# MB9BF51xR register map
File version: 1.7
Registers are 8-bit, read-write, reset 0x0 unless marked. A register's access mark holds for its fields unless they carry their own. Offsets are from the block's base; lines under a group give offsets from that group; [hi:lo] are bit positions; {n}, {i} and the like mark numbered series; 'fields as' and 'values as' point back to an identical list; <NAME> marks a mode.

## Memory map
0x200E0000 WORKFLASH_IF size 0xC — WorkFlash Memory
0x40000000 FLASH_IF blocks up to offset 0x104 — Flash Memory
0x40010000 CRG blocks up to offset 0x69 — Clock Unit Registers
0x40011000 HWWDT blocks up to offset 0xC04 — Hardware Watchdog Timer
0x40012000 SWWDT blocks up to offset 0xC04 — Software Watchdog Timer
0x40015000 DTIM blocks up to offset 0x3C — Dual Timer
0x40020000 MFT0 blocks up to offset 0xC2 — Multifunction Timer 0
0x40021000 MFT1 blocks up to offset 0xC2
0x40022000 MFT2 blocks up to offset 0xC2
0x40024000 MFT_PPG blocks up to offset 0x359 — PPG Configuration
0x40025000 BT0 blocks up to offset 0x12 — Base Timer 0
0x40025040 BT1 blocks up to offset 0x12
0x40025080 BT2 blocks up to offset 0x12
0x400250C0 BT3 blocks up to offset 0x12
0x40025100 BTIOSEL03 size 0x2 — Base Timer I/O Select
0x40025200 BT4 blocks up to offset 0x12
0x40025240 BT5 blocks up to offset 0x12
0x40025280 BT6 blocks up to offset 0x12
0x400252C0 BT7 blocks up to offset 0x12
0x40025300 BTIOSEL47 blocks up to offset 0x2 — Base Timer I/O Select
0x40025F00 SBSSR blocks up to offset 0xFE — Software-based Simultaneous Startup Register
0x40026000 QPRC0 blocks up to offset 0x40 — Quadrature Position/Revolution Counter 0
0x40026040 QPRC1 blocks up to offset 0x40
0x40026080 QPRC2 blocks up to offset 0x40
0x40027000 ADC0 blocks up to offset 0x3D — ADC0 Registers
0x40027100 ADC1 blocks up to offset 0x3D
0x40027200 ADC2 blocks up to offset 0x3D
0x4002E000 CRTRIM blocks up to offset 0x10 — CR Trimming Registers
0x40030000 EXTI blocks up to offset 0x19 — External Interrupt and NMI Control
0x40031000 INTREQ blocks up to offset 0x218 — Interrupts
0x40033000 GPIO size 0x740 — General-purpose I/O ports
0x40035000 LVD blocks up to offset 0x11 — Low-voltage Detection
0x40036000 USBCLK blocks up to offset 0x31 — USB Clock
0x40037000 CANPRES size 0x1 — CAN Prescaler Register
0x40038000 MFS0 blocks up to offset 0x12 — Multi-function Serial Interface 0
0x40038100 MFS1 blocks up to offset 0x12
0x40038200 MFS2 blocks up to offset 0x12
0x40038300 MFS3 blocks up to offset 0x12
0x40038400 MFS4 blocks up to offset 0x1A — Multi-function Serial Interface 4
0x40038500 MFS5 blocks up to offset 0x1A
0x40038600 MFS6 blocks up to offset 0x1A
0x40038700 MFS7 blocks up to offset 0x1A
0x40038800 MFS_NFC size 0x2 — I2C Auxiliary Noise Filter Setting Register
0x40039000 CRC blocks up to offset 0x10 — CRC Registers
0x4003A000 WC blocks up to offset 0x15 — Watch Counter
0x4003B000 RTC blocks up to offset 0x2A — REAL-TIME CLOCK
0x4003F000 EXBUS blocks up to offset 0x304 — External Bus Interface
0x40040000 USB0 blocks up to offset 0x2176 — USB0 Function
0x40060000 DMAC blocks up to offset 0x90 — DMAC Registers
0x40062000 CAN0 blocks up to offset 0xB4 — CAN0 Registers
0x40063000 CAN1 blocks up to offset 0xB4

## Interrupts
0 CSV (CRG)
1 SWDT (SWWDT)
2 LVD
3 WFG (MFT0)
4 EXTINT0_7 (EXTI)
5 EXTINT8_15 (EXTI)
6 DTIM_QDU (DTIM)
{2n+7} MFS{n}RX (MFS{n}) (n=0..7)
{2n+8} MFS{n}TX (MFS{n}) (n=0..7)
23 PPG (MFT_PPG)
24 OSC_PLL_WC (CRG)
25 ADC0
26 ADC1
27 ADC2
28 FRTIM (MFT0)
29 INCAP (MFT0)
30 OUTCOMP (MFT0)
31 BTIM0_7 (BT0)
32 CAN0
33 CAN1
34 USB0F (USB0)
35 USB0F_USB0H (USB0)
{n+38} DMAC{n} (DMAC) (n=0..7)

## WORKFLASH_IF — WorkFlash Memory
Base 0x200E0000
0x00 WFASZR 32-bit reset 0x1 — WorkFlash Access Size Register
  [0] ASZ — WorkFlash Access Size
0x04 WFRWTR 32-bit reset 0x2 — WorkFlash Read Wait Register
  [2:0] RWT — Read Wait Cycle
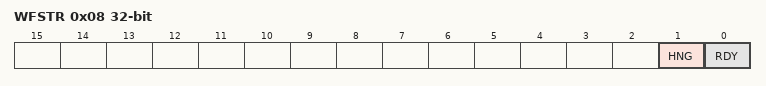
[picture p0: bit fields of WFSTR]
0x08 WFSTR 32-bit ro — WorkFlash Status Register
  [1] HNG — WorkFlash Hang
  [0] RDY — WorkFlash Rdy

## FLASH_IF — Flash Memory
Base 0x40000000
0x00 FASZR 32-bit reset 0x2 — Flash Access Size Register
  [1:0] ASZ — Flash Access Size
0x04 FRWTR 32-bit reset 0x2 — Flash Read Wait Register
  [1:0] RWT — Read Wait Cycle
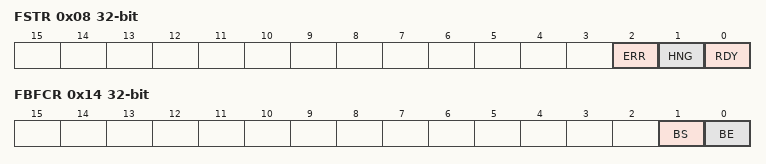
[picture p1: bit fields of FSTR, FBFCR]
0x08 FSTR 32-bit ro — Flash Status Register
  [2] ERR rw — Flash ECC Error
  [1] HNG — Flash Hang flag
  [0] RDY — Flash Rdy
0x10 FSYNDN 32-bit — Flash Sync Down Register
  [2:0] SD — Flash Sync
0x14 FBFCR 32-bit — Flash Buffer Control Register
  [1] BS ro — Buffer Status
  [0] BE — Buffer Enable
0x100 CRTRMM 32-bit ro reset not defined — CR Trimming Data Mirror Register
  [9:0] TRMM — CR Trimming Data Mirror

## Notices in the file
Licence Terms
FUJITSU SEMICONDUCTOR LIMITED (gLICENSORh) hereby grants and
you (gLICENSEEh) hereby accept a non transferable, non-exclusive
licence to use and copy the deliverables (gDeliverablesh) solely for
the purpose of; (i) developing LICENSEEfs development tools and
distributing such development tools to third parties; (ii) generating
derivative representations of the Deliverables to develop and debug
software for LICENSORfs targeted devices or device series identified
within the Deliverables, (together the gPurposeh) under the following
terms and conditions:
1. Ownership.
The Deliverables are the property of LICENSOR. LICENSEE acquires no
right, title or interest in the Deliverables other than the licence
rights granted herein.
2. Use.
LICENSEE shall only be permitted to use the Deliverables for the
Purpose. LICENSEE shall not reverse engineer, decompile or
disassemble the Deliverables, in whole or in part.
3. Copies.
All copies of the Deliverables must bear the same notice(s) contained
on the original copies of the Deliverables.
4. No Warranty.
THE DELIVERABLES ARE PROVIDED gAS ISh AND ANY EXPRESS, IMPLIED OR
STATUTORY WARRANTIES, INCLUDING, BUT NOT LIMITED TO, THE IMPLIED
WARRANTIES OF MERCHANTABILITY, SATISFACTORY QUALITY AND FITNESS FOR
A PARTICULAR PURPOSE ARE DISCLAIMED.
IN NO EVENT SHALL LICENSOR BE LIABLE FOR ANY DIRECT, INDIRECT,
INCIDENTAL, SPECIAL, EXEMPLARY, OR CONSEQUENTIAL DAMAGES HOWEVER CAUSED
AND ON ANY THEORY OF LIABILITY, WHETHER IN CONTRACT, STRICT LIABILITY,
OR TORT (INCLUDING NEGLIGENCE OR OTHERWISE) ARISING IN ANY WAY OUT OF
THE USE OF THE DELIVERABLES, EVEN IF ADVISED OF THE POSSIBILITY OF SUCH
DAMAGE.
LICENSEE EXPRESSLY ASSUMES ALL LIABILITIES AND RISKS, FOR USE OR
OPERATION OF THE DELIVERABLES.
5.In the event that LICENSEE receives early access to the Deliverables,
LICENSEE acknowledges and agrees that;
(a) notwithstanding the licence grants above, LICENSEE shall only be
permitted to use the Deliverables solely internally for evaluation and
providing feedback to LICENSOR;
(b) except with respect to the limited licence grants in 5(a), LICENSEE
shall be subject to all of the terms and conditions set out above; and
(c) the Deliverables are confidential information and LICENSEE shall
maintain in confidence the Deliverables and apply security measures no
less stringent than the measures that LICENSEE applies to its own like
information, but not less than a reasonable degree of care, to prevent
unauthorised disclosure and use of the Deliverables.
